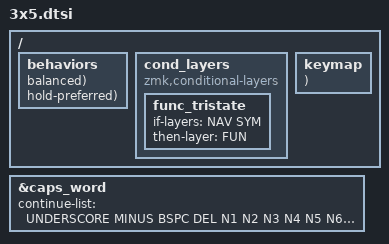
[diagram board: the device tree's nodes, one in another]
#include <behaviors.dtsi>
#include <dt-bindings/zmk/keys.h>
#include <dt-bindings/zmk/bt.h>
#include <dt-bindings/zmk/outputs.h>

// Common define for behavior
#define HM_BEHAVIOR(NAME, LABEL, B1, B2, HOLD, FLAVOR) \
    NAME { \
        compatible = "zmk,behavior-hold-tap"; \
        label = #LABEL; \
        #binding-cells = <2>; \
        flavor = #FLAVOR; \
        tapping-term-ms = <200>; \
        quick-tap-ms = <150>; \
        bindings = B1, B2; \
        hold-trigger-key-positions = <HOLD>; \
        hold-trigger-on-release; \
    }

// Layer macro
#define LAYER(NAME, ...)\
    compatible = "zmk,keymap"; \
    NAME##_layer { \
        label = #NAME; \
        bindings = <__VA_ARGS__>; \
    } 


// Layer aliases
#define CMK  0
#define SYM  1
#define NAV  2
#define FUN  3
#define MCL  4
#define MCR  5

// Desktop keycodes
#define D_LT   LC(LA(LEFT))
#define D_RT   LC(LA(RIGHT))

// Browser keycodes
#define TAB_NW LC(T)
#define TAB_RT LC(TAB)
#define TAB_LT LC(LS(TAB))
#define TAB_CL LC(W)

// VS Code keycodes
#define CDE_BK LC(LA(MINUS))
#define CDE_FD LC(LS(MINUS))

// Key position groups
#define KEYS_L 0 1 2 3 4 10 11 12 13 14 20 21 22 23 24
#define KEYS_R 5 6 7 8 9 15 16 17 18 19 25 26 27 28 29
#define THUMBS 30 31 32 33 34 35 

#include "combos.dtsi"

&caps_word {
    continue-list = <UNDERSCORE MINUS BSPC DEL N1 N2 N3 N4 N5 N6 N7 N8 N9 N0>;
};

/ {
    behaviors {        
        HM_BEHAVIOR(hml: homerow_mods_left, HM Left, <&kp>, <&kp>, KEYS_R THUMBS, balanced);
        HM_BEHAVIOR(hmr: homerow_mods_right, HM Right, <&kp>, <&kp>, KEYS_L THUMBS, balanced);
        HM_BEHAVIOR(hmt: homerow_mod_toggle, HM Toggle, <&mo>, <&kp>, KEYS_L KEYS_R, balanced);

        HM_BEHAVIOR(ltr: layer_toggle_right, Layer Toggle Right, <&mo>, <&kp>, KEYS_L KEYS_R, balanced);
        HM_BEHAVIOR(ltl: layer_toggle_left, Layer Toggle Left, <&mo>, <&kp>, KEYS_L KEYS_R, hold-preferred);
    };

    cond_layers {
        compatible = "zmk,conditional-layers";
        // Define FUN layer as tri-state
        func_tristate {
            if-layers = <NAV SYM>;
            then-layer = <FUN>;
        };
    };

    keymap {
        LAYER(Qwerty,
// ╭─────────────┬─────────────┬─────────────┬─────────────┬─────────────╮   ╭─────────────┬─────────────┬─────────────┬─────────────┬─────────────╮
     &kp Q         &kp W         &kp E         &kp R         &kp T             &kp Y         &kp U         &kp I         &kp O         &kp P
// ├─────────────┼─────────────┼─────────────┼─────────────┼─────────────┤   ├─────────────┼─────────────┼─────────────┼─────────────┼─────────────┤
     &hml LCTRL A  &hml LGUI S   &hml LALT D   &hml LSHFT F  &hmt MCL G         &hmt MCR H    &hmr RSHFT J  &hmr RALT K   &hmr RGUI L   &hmr RCTRL COLON
// ├─────────────┼─────────────┼─────────────┼─────────────┼─────────────┤   ├─────────────┼─────────────┼─────────────┼─────────────┼─────────────┤
     &kp Z         &kp X         &kp C         &kp V         &kp B             &kp N         &kp M        &kp COMMA     &kp DOT       &kp SLASH
// ╰─────────────┴─────────────┴─────────────┼─────────────┼─────────────┤   ├─────────────┼─────────────┼─────────────┴─────────────┴─────────────╯
                                 &mt LGUI ESC  &mt LCTRL RET &ltr NAV SPACE    &ltl SYM BSPC &mt RSHFT TAB &mt RALT DEL
//                             ╰─────────────┴─────────────┴─────────────╯   ╰─────────────┴─────────────┴─────────────╯
        );

        LAYER(Symbols,
// ╭─────────────┬─────────────┬─────────────┬─────────────┬─────────────╮   ╭─────────────┬─────────────┬─────────────┬─────────────┬─────────────╮
     &kp EXCL      &kp AT        &kp HASH      &kp DLLR      &kp PRCNT         &kp PLUS      &kp N7        &kp N8        &kp N9        &kp STAR
// ├─────────────┼─────────────┼─────────────┼─────────────┼─────────────┤   ├─────────────┼─────────────┼─────────────┼─────────────┼─────────────┤
     &hml LCTRL PLUS &hml LGUI EQUAL &hml LALT UNDER &hml LSHFT MINUS &kp CARET &kp MINUS    &hmr RSHFT N4 &hmr RALT N5 &hmr RGUI N6 &hmr RCTRL SLASH  
// ├─────────────┼─────────────┼─────────────┼─────────────┼─────────────┤   ├─────────────┼─────────────┼─────────────┼─────────────┼─────────────┤
     &kp TILDE     &kp PIPE      &kp BSLH      &kp STAR      &kp AMPS          &kp N0        &kp N1        &kp N2        &kp N3        &kp DOT
// ╰─────────────┴─────────────┴─────────────┼─────────────┼─────────────┤   ├─────────────┼─────────────┼─────────────┴─────────────┴─────────────╯
                                 &mt LGUI ESC  &mt LCTRL RET &trans          &trans          &mt RSHFT TAB &mt RALT COMMA
//                             ╰─────────────┴─────────────┴─────────────╯   ╰─────────────┴─────────────┴─────────────╯
        );

        LAYER(Navigation,
// ╭─────────────┬─────────────┬─────────────┬─────────────┬─────────────╮   ╭─────────────┬─────────────┬─────────────┬─────────────┬─────────────╮
     &kp D_LT      &kp PG_UP     &kp UP        &kp PG_DN      &kp D_RT          &kp HOME      &kp PG_DN     &kp PG_UP    &kp END        &trans
// ├─────────────┼─────────────┼─────────────┼─────────────┼─────────────┤   ├─────────────┼─────────────┼─────────────┼─────────────┼─────────────┤
     &hml LCTRL HOME &hml LGUI LEFT &hml LALT DOWN &hml LSHFT RIGHT &kp END      &kp LEFT  &hmr RSHFT DOWN &hmr RALT UP &hmr RGUI RIGHT &hmr RCTRL C_AL_CALC  
// ├─────────────┼─────────────┼─────────────┼─────────────┼─────────────┤   ├─────────────┼─────────────┼─────────────┼─────────────┼─────────────┤
     &kp TAB_CL    &kp TAB_LT    &kp TAB_NW    &kp TAB_RT     &kp CDE_BK        &kp CDE_FD    &kp INS      &kp DEL       &trans         &trans
// ╰─────────────┴─────────────┴─────────────┼─────────────┼─────────────┤   ├─────────────┼─────────────┼─────────────┴─────────────┴─────────────╯
                                 &mt LGUI ESC  &mt LCTRL RET &trans         &trans            &mt RSHFT TAB &mt RALT DEL
//                             ╰─────────────┴─────────────┴─────────────╯   ╰─────────────┴─────────────┴─────────────╯
        );


        LAYER(Function,
// ╭─────────────┬─────────────┬─────────────┬─────────────┬─────────────╮   ╭─────────────┬─────────────┬─────────────┬─────────────┬─────────────╮
     &kp F1        &kp F2        &kp F3        &kp F4        &kp F5            &bt BT_SEL 0  &bt BT_SEL 1  &bt BT_SEL 2  &bt BT_SEL 3  &bt BT_SEL 4
// ├─────────────┼─────────────┼─────────────┼─────────────┼─────────────┤   ├─────────────┼─────────────┼─────────────┼─────────────┼─────────────┤
     &kp F6        &kp F7        &kp F8        &kp F9        &kp F10           &kp CAPS      &kp LSHIFT    &kp LALT      &kp LGUI      &kp LCTRL
// ├─────────────┼─────────────┼─────────────┼─────────────┼─────────────┤   ├─────────────┼─────────────┼─────────────┼─────────────┼─────────────┤
     &trans        &trans        &trans        &kp F11       &kp F12           &out OUT_USB  &out OUT_BLE  &kp PSCRN    &kp PAUSE_BREAK &bt BT_CLR
// ╰─────────────┴─────────────┴─────────────┼─────────────┼─────────────┤   ├─────────────┼─────────────┼─────────────┴─────────────┴─────────────╯
                                  &trans        &kp LCTRL      &trans            &trans        &kp RSHIFT     &trans
//                             ╰─────────────┴─────────────┴─────────────╯   ╰─────────────┴─────────────┴─────────────╯
        );

        LAYER(MiscL,
// ╭─────────────┬─────────────┬─────────────┬─────────────┬─────────────╮   ╭─────────────┬─────────────┬─────────────┬─────────────┬─────────────╮
       &bootloader   &sys_reset    &trans        &trans        &trans            &trans        &trans        &trans        &sys_reset    &bootloader
// ├─────────────┼─────────────┼─────────────┼─────────────┼─────────────┤   ├─────────────┼─────────────┼─────────────┼─────────────┼─────────────┤
       &kp K_LOCK    &trans        &trans        &trans        &trans            &trans        &trans        &trans        &trans        &kp K_LOCK
// ├─────────────┼─────────────┼─────────────┼─────────────┼─────────────┤   ├─────────────┼─────────────┼─────────────┼─────────────┼─────────────┤
       &trans        &trans        &trans        &trans        &trans            &trans        &trans        &trans        &trans        &trans
// ╰─────────────┴─────────────┴─────────────┼─────────────┼─────────────┤   ├─────────────┼─────────────┼─────────────┴─────────────┴─────────────╯
                                   &kp DEL       &kp TAB       &kp BSPC           &kp SPACE     &kp RET     &kp ESC
//                             ╰─────────────┴─────────────┴─────────────╯   ╰─────────────┴─────────────┴─────────────╯
        );

        LAYER(MiscR,
// ╭─────────────┬─────────────┬─────────────┬─────────────┬─────────────╮   ╭─────────────┬─────────────┬─────────────┬─────────────┬─────────────╮
     &kp C_REWIND  &kp C_PREV    &kp C_PP      &kp C_NEXT    &kp C_VOL_UP        &trans        &trans        &trans        &sys_reset    &bootloader
// ├─────────────┼─────────────┼─────────────┼─────────────┼─────────────┤   ├─────────────┼─────────────┼─────────────┼─────────────┼─────────────┤
       &trans        &trans       &kp C_STOP     &trans      &kp C_VOL_DN        &trans        &trans        &trans        &trans        &kp K_LOCK
// ├─────────────┼─────────────┼─────────────┼─────────────┼─────────────┤   ├─────────────┼─────────────┼─────────────┼─────────────┼─────────────┤
       &trans        &trans        &trans        &trans      &kp C_MUTE          &trans        &trans        &trans        &trans        &trans
// ╰─────────────┴─────────────┴─────────────┼─────────────┼─────────────┤   ├─────────────┼─────────────┼─────────────┴─────────────┴─────────────╯
                                   &kp DEL       &kp TAB       &kp BSPC           &kp SPACE     &kp RET     &kp ESC
//                             ╰─────────────┴─────────────┴─────────────╯   ╰─────────────┴─────────────┼─────────────╯
        );
    };
};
